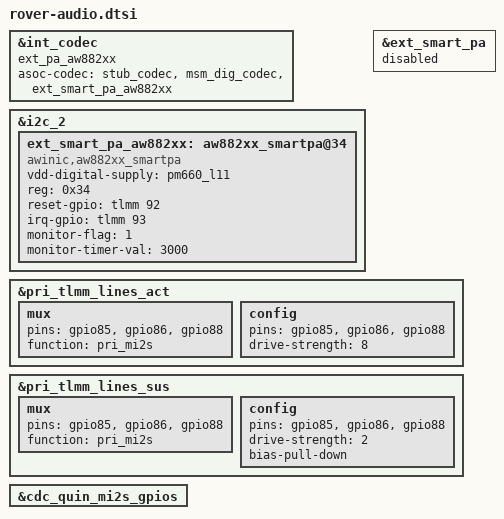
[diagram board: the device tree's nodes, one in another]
&int_codec{
	ext_pa_aw882xx;
	asoc-codec = <&stub_codec>, <&msm_dig_codec>, <&ext_smart_pa_aw882xx>;
};
&i2c_2{
	ext_smart_pa_aw882xx: aw882xx_smartpa@34 {
		compatible = "awinic,aw882xx_smartpa";
		vdd-digital-supply = <&pm660_l11>;
		reg = <0x34>;
		reset-gpio = <&tlmm 92 0>;
		irq-gpio = <&tlmm 93 0x2008>;
		monitor-flag = <1>;
		monitor-timer-val = <3000>;
		status = "okay";
	};
};
&ext_smart_pa{
	status = "disabled";
};

&pri_tlmm_lines_act {
	mux {
		pins = "gpio85", "gpio86", "gpio88";
		function = "pri_mi2s";
	};

	config {
		pins = "gpio85", "gpio86", "gpio88";
		drive-strength = <8>;
	};
};

&pri_tlmm_lines_sus {
	mux {
		pins = "gpio85", "gpio86", "gpio88";
		function = "pri_mi2s";
	};

	config {
		pins = "gpio85", "gpio86", "gpio88";
		drive-strength = <2>;
		bias-pull-down;
	};
};

&cdc_quin_mi2s_gpios {
	status = "okay";
};
